# M5531 register map
File version: 1.0
Registers are 32-bit, read-write, reset 0x0 unless marked. A register's access mark holds for its fields unless they carry their own. Offsets are from the block's base; [hi:lo] are bit positions; {n}, {i} and the like mark numbered series.

## WWDT0 — WWDT Register Map
Base 0x40240000
Same registers: WWDT1 0x40280000, WWDT0_NS 0x50240000, WWDT1_NS 0x50280000
0x00 WWDT_RLDCNT wo — WWDT Reload Counter Register
  [31:0] RLDCNT — WWDT Reload Counter Register. Writing 0x00005AA5 to this register will reload the WWDT counter value to 0x3F. Note: User can only write WWDT_RLDCNT register to reload WWDT counter value when current WWDT counter value between 0 and CMPDAT (WWDT_CTL[21:16]). If user writes WWDT_RLDCNT when current WWDT counter value is larger than CMPDAT, WWDT reset signal will be generated immediately. Note 2 :Performing to RLDCNT needs 3 * WWDT_CLK period to become active.
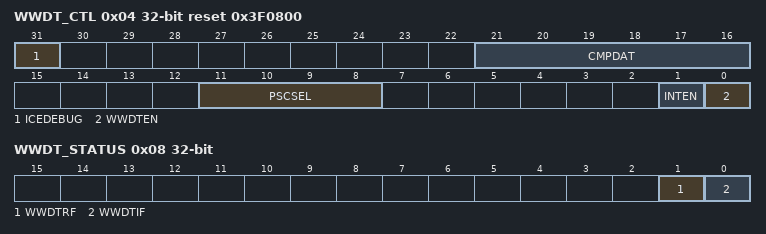
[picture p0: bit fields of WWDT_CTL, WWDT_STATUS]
0x04 WWDT_CTL reset 0x3F0800 — WWDT Control Register
  [31] ICEDEBUG — ICE Debug Mode Acknowledge Disable Bit. Note: WWDT down counter will keep going no matter CPU is held by ICE or not.
    0=ICE debug mode acknowledgement effects WWDT counting; 1=ICE debug mode acknowledgement Disabled
  [21:16] CMPDAT — WWDT Window Compare. Set this register to adjust the valid reload window. Note: User can only write WWDT_RLDCNT register to reload WWDT counter value when current WWDT counter value between 0 and CMPDAT. If user writes WWDT_RLDCNT register when current WWDT counter value larger than CMPDAT, WWDT reset signal will generate immediately.
  [11:8] PSCSEL — WWDT Counter Prescale Period Selection
    0=Pre-scale is 1; Max time-out period is 1 * 64 * WWDT_CLK; 1=Pre-scale is 2; Max time-out period is 2 * 64 * WWDT_CLK; 2=Pre-scale is 4; Max time-out period is 4 * 64 * WWDT_CLK; 3=Pre-scale is 8; Max time-out period is 8 * 64 * WWDT_CLK; 4=Pre-scale is 16; Max time-out period is 16 * 64 * WWDT_CLK; 5=Pre-scale is 32; Max time-out period is 32 * 64 * WWDT_CLK; 6=Pre-scale is 64; Max time-out period is 64 * 64 * WWDT_CLK; 7=Pre-scale is 128; Max time-out period is 128 * 64 * WWDT_CLK; 8=Pre-scale is 192; Max time-out period is 192 * 64 * WWDT_CLK; 9=Pre-scale is 256; Max time-out period is 256 * 64 * WWDT_CLK; 10=Pre-scale is 384; Max time-out period is 384 * 64 * WWDT_CLK; 11=Pre-scale is 512; Max time-out period is 512 * 64 * WWDT_CLK; 12=Pre-scale is 768; Max time-out period is 768 * 64 * WWDT_CLK; 13=Pre-scale is 1024; Max time-out period is 1024 * 64 * WWDT_CLK; 14=Pre-scale is 1536; Max time-out period is 1536 * 64 * WWDT_CLK; 15=Pre-scale is 2048; Max time-out period is 2048 * 64 * WWDT_CLK
  [1] INTEN — WWDT Interrupt Enable Bit. If this bit is enabled, the WWDT counter compare match interrupt signal is generated and inform to CPU.
    0=WWDT counter compare match interrupt Disabled; 1=WWDT counter compare match interrupt Enabled
  [0] WWDTEN — WWDT Enable Bit
    0=WWDT counter is stopped; 1=WWDT counter starts counting
0x08 WWDT_STATUS
  [1] WWDTRF — WWDT Timer-out Reset Flag. This bit indicates the system has been reset by WWDT time-out reset or not. Note: This bit is cleared by writing 1 to it.
    0=WWDT time-out reset did not occur; 1=WWDT time-out reset occurred
  [0] WWDTIF — WWDT Compare Match Interrupt Flag. This bit indicates the interrupt flag status of WWDT while WWDT counter value matches CMPDAT (WWDT_CTL[21:16]). Note: This bit is cleared by writing 1 to it.
    0=No effect; 1=WWDT counter value matches CMPDAT
0x0C WWDT_CNT ro reset 0x3F — WWDT Counter Value Register
  [5:0] CNTDAT — WWDT Counter Value. CNTDAT will be updated continuously to monitor 6-bit WWDT down counter value.

## AWF — AWF Register Map
Base 0x40449000
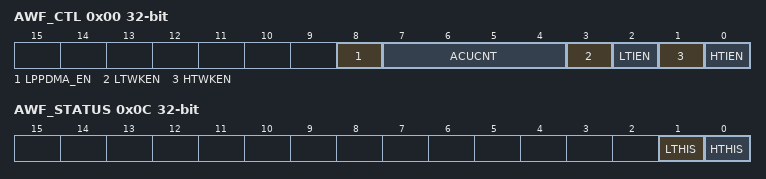
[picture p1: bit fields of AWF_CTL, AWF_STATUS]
0x00 AWF_CTL — AWF Control Register
  [8] LPPDMA_EN — LPPDMA Enable Bit. This bit is used to enable LPPDMA to access AWF when chip is in NPD0/1/3.
    0=LPPDMA can't access AWF when chip is in NPD0/1/3; 1=LPPDMA can access AWF when chip is in NPD0/1/3
  [7:4] ACUCNT — Accumulation Count. The counter defines the acculated data to compare with high threshold and low threshold.The allowed maximum value is 8. If the write value is larger than 8, ACUCNT will become 0.
  [3] LTWKEN — AWF Low Threshold Wake Up Enable Bit
    0=AWF low threshold wake up Disabled; 1=AWF low threshold wake up Enabled
  [2] LTIEN — AWF Low Threshold Interrupt Enable Bit
    0=AWF low threshold interrupt Disabled; 1=AWF low threshold interrupt Enabled
  [1] HTWKEN — AWF High Threshold Wake Up Enable Bit
    0=AWF high threshold wake up Disabled; 1=AWF high threshold wake up Enabled
  [0] HTIEN — AWF High Threshold Interrupt Enable Bit
    0=AWF high threshold interrupt Disabled; 1=AWF high threshold interrupt Enabled
0x04 AWF_HTH — AWF High Threshold Value Register
  [18:0] AWFHTH — AWF High Threshold Value Register. If the accumulated value exceeds the high threshold value, comparing function will activate once set interrupt enable respectively.
0x08 AWF_LTH — AWF Low Threshold Value Register
  [18:0] AWFLTH — AWF Low Threshold Value Register. If the accumulated value is less than the low threshold value, comparing function will activate once set interrupt enable respectively.
0x0C AWF_STATUS
  [1] LTHIS — AWF LTH Interupt Flag. Note: This bit is set to 1 when ACUCNT is not zero and accumulation data is less than LTH. User writes 1 to clear this bit to 0. This bit wil keep 1 if accumulation data is less than LTH after user writes 1 to clear.
    0=AWF LTH interrupt event has not occurred; 1=AWF LTH interrupt event occurs
  [0] HTHIS — AWF HTH Interupt Flag. Note: This bit is set to 1 when ACUCNT is not zero and accumulation data is over than HTH. User writes 1 to clear this bit to 0. This bit will keep 1 if accumulation data is over than HTH after user writes 1 to clear.
    0=AWF HTH interrupt event has not occurred; 1=AWF HTH interrupt event occurs
0x10 AWF_WBINIT — AWF Word Buffer Initial Value Register
  [15:0] WBINIT — AWF Word Buffer Initial Value. Writing this register will update WBINIT into all word registers (AWF_W0 ~ AWF_W7). WBINIT will also be updated into all word registers (AWF_W0 ~ AWF_W7) once ACUCNT is updated.
0x1C AWF_DAT — AWF Data Holding Register
  [15:0] AWFDAT — AWF Data Holding Register. These bits are written by user software and will be filled in circularly from word0 to word[ACUCNT-1].
{0x20+4i} AWF_W{i} ro (i=0..7) — AWF Word Register {i}
  [15:0] WORD — AWF Word Register. Word will accumulate from Word0 to Word[ACUCNT-1], and will compare with AWF_HTH and AWF_LTH.
0x40 AWF_ACUVAL ro — AWF Accumulated Value Register
  [18:0] ACUVAL — AWF Accumulated Value Register. Accumulated value will be accumulated from word0 to word[ACUCNT-1].
